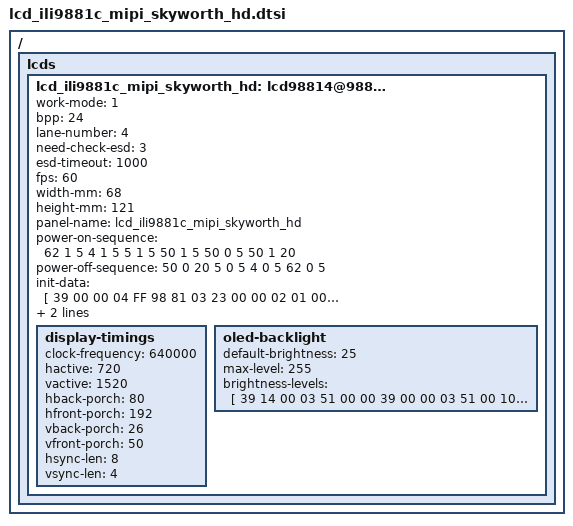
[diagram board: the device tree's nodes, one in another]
/ { lcds {
	lcd_ili9881c_mipi_skyworth_hd: lcd98814@98814 {

		work-mode = <1>;
		bpp = <24>;
		lane-number = <4>;

		need-check-esd = <3>;
		esd-timeout = <1000>;

		fps = <60>;
		width-mm = <68>;
		height-mm = <121>;
		panel-name = "lcd_ili9881c_mipi_skyworth_hd";

		power-on-sequence = <
					62  1  5
					4   1  5
					5   1  5
					50  1  5
					50  0  5
					50  1  20
					>;
		power-off-sequence = <
					50  0  20
					5   0	5
					4   0   5
					62  0  5
					>;

		init-data = [
			39 00 00 04 FF 98 81 03
			23 00 00 02 01 00
			23 00 00 02 02 00
			23 00 00 02 03 53
			23 00 00 02 04 53
			23 00 00 02 05 13
			23 00 00 02 06 04
			23 00 00 02 07 02
			23 00 00 02 08 02
			23 00 00 02 09 00
			23 00 00 02 0a 00
			23 00 00 02 0b 00
			23 00 00 02 0c 00
			23 00 00 02 0d 00
			23 00 00 02 0e 00
			23 00 00 02 0f 00
			23 00 00 02 10 00
			23 00 00 02 11 00
			23 00 00 02 12 00
			23 00 00 02 13 00
			23 00 00 02 14 00
			23 00 00 02 15 00
			23 00 00 02 16 00
			23 00 00 02 17 00
			23 00 00 02 18 00
			23 00 00 02 19 00
			23 00 00 02 1a 00
			23 00 00 02 1b 00
			23 00 00 02 1c 00
			23 00 00 02 1d 00
			23 00 00 02 1e C0
			23 00 00 02 1f 80
			23 00 00 02 20 02
			23 00 00 02 21 09
			23 00 00 02 22 00
			23 00 00 02 23 00
			23 00 00 02 24 00
			23 00 00 02 25 00
			23 00 00 02 26 00
			23 00 00 02 27 00
			23 00 00 02 28 55
			23 00 00 02 29 03
			23 00 00 02 2a 00
			23 00 00 02 2b 00
			23 00 00 02 2c 00
			23 00 00 02 2d 00
			23 00 00 02 2e 00
			23 00 00 02 2f 00
			23 00 00 02 30 00
			23 00 00 02 31 00
			23 00 00 02 32 00
			23 00 00 02 33 00
			23 00 00 02 34 03
			23 00 00 02 35 00
			23 00 00 02 36 05
			23 00 00 02 37 00
			23 00 00 02 38 3C
			23 00 00 02 39 00
			23 00 00 02 3a 00
			23 00 00 02 3b 00
			23 00 00 02 3c 00
			23 00 00 02 3d 00
			23 00 00 02 3e 00
			23 00 00 02 3f 00
			23 00 00 02 40 00
			23 00 00 02 41 00
			23 00 00 02 42 00
			23 00 00 02 43 00
			23 00 00 02 44 00
			23 00 00 02 50 01
			23 00 00 02 51 23
			23 00 00 02 52 45
			23 00 00 02 53 67
			23 00 00 02 54 89
			23 00 00 02 55 ab
			23 00 00 02 56 01
			23 00 00 02 57 23
			23 00 00 02 58 45
			23 00 00 02 59 67
			23 00 00 02 5a 89
			23 00 00 02 5b ab
			23 00 00 02 5c cd
			23 00 00 02 5d ef
			23 00 00 02 5e 01
			23 00 00 02 5f 02
			23 00 00 02 60 02
			23 00 00 02 61 0A
			23 00 00 02 62 08
			23 00 00 02 63 14
			23 00 00 02 64 15
			23 00 00 02 65 0C
			23 00 00 02 66 0D
			23 00 00 02 67 0E
			23 00 00 02 68 0F
			23 00 00 02 69 10
			23 00 00 02 6a 11
			23 00 00 02 6b 06
			23 00 00 02 6c 02
			23 00 00 02 6d 02
			23 00 00 02 6e 02
			23 00 00 02 6f 02
			23 00 00 02 70 02
			23 00 00 02 71 02
			23 00 00 02 72 00
			23 00 00 02 73 02
			23 00 00 02 74 02
			23 00 00 02 75 02
			23 00 00 02 76 02
			23 00 00 02 77 0A
			23 00 00 02 78 06
			23 00 00 02 79 14
			23 00 00 02 7a 15
			23 00 00 02 7b 0F
			23 00 00 02 7c 0E
			23 00 00 02 7d 0D
			23 00 00 02 7e 0C
			23 00 00 02 7f 11
			23 00 00 02 80 10
			23 00 00 02 81 08
			23 00 00 02 82 02
			23 00 00 02 83 02
			23 00 00 02 84 02
			23 00 00 02 85 02
			23 00 00 02 86 02
			23 00 00 02 87 02
			23 00 00 02 88 02
			23 00 00 02 89 02
			23 00 00 02 8A 02
			39 00 00 04 FF 98 81 04
			23 00 00 02 00 82
			23 00 00 02 6C 15
			23 00 00 02 6E 2F
			23 00 00 02 6F 35
			23 00 00 02 3A 92
			23 00 00 02 8D 1F
			23 00 00 02 87 BA
			23 00 00 02 26 76
			23 00 00 02 B2 D1
			23 00 00 02 88 0B
			23 00 00 02 33 14
			23 00 00 02 35 1F
			23 00 00 02 38 01
			23 00 00 02 39 00
			23 00 00 02 7A 0F
			23 00 00 02 B5 06
			23 00 00 02 31 75
			23 00 00 02 3B 98
			39 00 00 04 FF 98 81 01
			23 00 00 02 22 0A
			23 00 00 02 31 00
			23 00 00 02 53 63
			23 00 00 02 55 6E
			23 00 00 02 50 E1
			23 00 00 02 51 DD
			23 00 00 02 60 28
			23 00 00 02 61 00
			23 00 00 02 62 10
			23 00 00 02 63 00
			23 00 00 02 70 51
			23 00 00 02 71 01
			23 00 00 02 2E 04
			23 00 00 02 2F 80
			23 00 00 02 A0 00
			23 00 00 02 A1 14
			23 00 00 02 A2 24
			23 00 00 02 A3 16
			23 00 00 02 A4 1B
			23 00 00 02 A5 2E
			23 00 00 02 A6 22
			23 00 00 02 A7 23
			23 00 00 02 A8 7E
			23 00 00 02 A9 1B
			23 00 00 02 AA 27
			23 00 00 02 AB 65
			23 00 00 02 AC 1A
			23 00 00 02 AD 19
			23 00 00 02 AE 4E
			23 00 00 02 AF 22
			23 00 00 02 B0 29
			23 00 00 02 B1 4A
			23 00 00 02 B2 5B
			23 00 00 02 B3 33
			23 00 00 02 C0 00
			23 00 00 02 C1 14
			23 00 00 02 C2 23
			23 00 00 02 C3 16
			23 00 00 02 C4 1A
			23 00 00 02 C5 2E
			23 00 00 02 C6 22
			23 00 00 02 C7 23
			23 00 00 02 C8 7E
			23 00 00 02 C9 1B
			23 00 00 02 CA 27
			23 00 00 02 CB 64
			23 00 00 02 CC 1A
			23 00 00 02 CD 19
			23 00 00 02 CE 4E
			23 00 00 02 CF 22
			23 00 00 02 D0 29
			23 00 00 02 D1 4A
			23 00 00 02 D2 5B
			23 00 00 02 D3 33
			39 00 00 04 FF 98 81 02
			23 00 00 02 06 20
			23 00 00 02 07 00
			39 00 00 04 FF 98 81 00
			39 00 00 03 68 04 00
			39 00 00 03 51 00 00
			23 00 00 02 53 24
			23 00 00 02 55 01
			39 00 00 03 5E 00 10
			23 00 00 02 35 00
			13 78 00 01 11
			13 14 00 01 29
			];
		sleep-in = [
			13 0A 00 01 28
			13 78 00 01 10
			];
		sleep-out = [
			13 78 00 01 11
			13 64 00 01 29
			];

		display-timings {
			clock-frequency = <640000>;
			hactive = <720>;
			vactive = <1520>;
			hback-porch = <80>;
			hfront-porch = <192>;
			vback-porch = <26>;
			vfront-porch = <50>;
			hsync-len = <8>;
			vsync-len = <4>;
		};
		oled-backlight {
			default-brightness = <25>;
			max-level = <255>;
			brightness-levels = [
				39 14 00 03 51 00 00
				39 00 00 03 51 00 10
				39 00 00 03 51 00 20
				39 00 00 03 51 00 30
				39 00 00 03 51 00 40
				39 00 00 03 51 00 50
				39 00 00 03 51 00 60
				39 00 00 03 51 00 70
				39 00 00 03 51 00 80
				39 00 00 03 51 00 90
				39 00 00 03 51 00 A0
				39 00 00 03 51 00 B0
				39 00 00 03 51 00 C0
				39 00 00 03 51 00 D0
				39 00 00 03 51 00 E0
				39 00 00 03 51 00 F0
				39 00 00 03 51 01 00
				39 00 00 03 51 01 10
				39 00 00 03 51 01 20
				39 00 00 03 51 01 30
				39 00 00 03 51 01 40
				39 00 00 03 51 01 50
				39 00 00 03 51 01 60
				39 00 00 03 51 01 70
				39 00 00 03 51 01 80
				39 00 00 03 51 01 90
				39 00 00 03 51 01 A0
				39 00 00 03 51 01 B0
				39 00 00 03 51 01 C0
				39 00 00 03 51 01 D0
				39 00 00 03 51 01 E0
				39 00 00 03 51 01 F0
				39 00 00 03 51 02 00
				39 00 00 03 51 02 10
				39 00 00 03 51 02 20
				39 00 00 03 51 02 30
				39 00 00 03 51 02 40
				39 00 00 03 51 02 50
				39 00 00 03 51 02 60
				39 00 00 03 51 02 70
				39 00 00 03 51 02 80
				39 00 00 03 51 02 90
				39 00 00 03 51 02 A0
				39 00 00 03 51 02 B0
				39 00 00 03 51 02 C0
				39 00 00 03 51 02 D0
				39 00 00 03 51 02 E0
				39 00 00 03 51 02 F0
				39 00 00 03 51 03 00
				39 00 00 03 51 03 10
				39 00 00 03 51 03 20
				39 00 00 03 51 03 30
				39 00 00 03 51 03 40
				39 00 00 03 51 03 50
				39 00 00 03 51 03 60
				39 00 00 03 51 03 70
				39 00 00 03 51 03 80
				39 00 00 03 51 03 90
				39 00 00 03 51 03 A0
				39 00 00 03 51 03 B0
				39 00 00 03 51 03 C0
				39 00 00 03 51 03 D0
				39 00 00 03 51 03 E0
				39 00 00 03 51 03 F0
				39 00 00 03 51 04 00
				39 00 00 03 51 04 10
				39 00 00 03 51 04 20
				39 00 00 03 51 04 30
				39 00 00 03 51 04 40
				39 00 00 03 51 04 50
				39 00 00 03 51 04 60
				39 00 00 03 51 04 70
				39 00 00 03 51 04 80
				39 00 00 03 51 04 90
				39 00 00 03 51 04 A0
				39 00 00 03 51 04 B0
				39 00 00 03 51 04 C0
				39 00 00 03 51 04 D0
				39 00 00 03 51 04 E0
				39 00 00 03 51 04 F0
				39 00 00 03 51 05 00
				39 00 00 03 51 05 10
				39 00 00 03 51 05 20
				39 00 00 03 51 05 30
				39 00 00 03 51 05 40
				39 00 00 03 51 05 50
				39 00 00 03 51 05 60
				39 00 00 03 51 05 70
				39 00 00 03 51 05 80
				39 00 00 03 51 05 90
				39 00 00 03 51 05 A0
				39 00 00 03 51 05 B0
				39 00 00 03 51 05 C0
				39 00 00 03 51 05 D0
				39 00 00 03 51 05 E0
				39 00 00 03 51 05 F0
				39 00 00 03 51 06 00
				39 00 00 03 51 06 10
				39 00 00 03 51 06 20
				39 00 00 03 51 06 30
				39 00 00 03 51 06 40
				39 00 00 03 51 06 50
				39 00 00 03 51 06 60
				39 00 00 03 51 06 70
				39 00 00 03 51 06 80
				39 00 00 03 51 06 90
				39 00 00 03 51 06 A0
				39 00 00 03 51 06 B0
				39 00 00 03 51 06 C0
				39 00 00 03 51 06 D0
				39 00 00 03 51 06 E0
				39 00 00 03 51 06 F0
				39 00 00 03 51 07 00
				39 00 00 03 51 07 10
				39 00 00 03 51 07 20
				39 00 00 03 51 07 30
				39 00 00 03 51 07 40
				39 00 00 03 51 07 50
				39 00 00 03 51 07 60
				39 00 00 03 51 07 70
				39 00 00 03 51 07 80
				39 00 00 03 51 07 90
				39 00 00 03 51 07 A0
				39 00 00 03 51 07 B0
				39 00 00 03 51 07 C0
				39 00 00 03 51 07 D0
				39 00 00 03 51 07 E0
				39 00 00 03 51 07 F0
				39 00 00 03 51 08 00
				39 00 00 03 51 08 10
				39 00 00 03 51 08 20
				39 00 00 03 51 08 30
				39 00 00 03 51 08 40
				39 00 00 03 51 08 50
				39 00 00 03 51 08 60
				39 00 00 03 51 08 70
				39 00 00 03 51 08 80
				39 00 00 03 51 08 90
				39 00 00 03 51 08 A0
				39 00 00 03 51 08 B0
				39 00 00 03 51 08 C0
				39 00 00 03 51 08 D0
				39 00 00 03 51 08 E0
				39 00 00 03 51 08 F0
				39 00 00 03 51 09 00
				39 00 00 03 51 09 10
				39 00 00 03 51 09 20
				39 00 00 03 51 09 30
				39 00 00 03 51 09 40
				39 00 00 03 51 09 50
				39 00 00 03 51 09 60
				39 00 00 03 51 09 70
				39 00 00 03 51 09 80
				39 00 00 03 51 09 90
				39 00 00 03 51 09 A0
				39 00 00 03 51 09 B0
				39 00 00 03 51 09 C0
				39 00 00 03 51 09 D0
				39 00 00 03 51 09 E0
				39 00 00 03 51 09 F0
				39 00 00 03 51 0A 00
				39 00 00 03 51 0A 10
				39 00 00 03 51 0A 20
				39 00 00 03 51 0A 30
				39 00 00 03 51 0A 40
				39 00 00 03 51 0A 50
				39 00 00 03 51 0A 60
				39 00 00 03 51 0A 70
				39 00 00 03 51 0A 80
				39 00 00 03 51 0A 90
				39 00 00 03 51 0A A0
				39 00 00 03 51 0A B0
				39 00 00 03 51 0A C0
				39 00 00 03 51 0A D0
				39 00 00 03 51 0A E0
				39 00 00 03 51 0A F0
				39 00 00 03 51 0B 00
				39 00 00 03 51 0B 10
				39 00 00 03 51 0B 20
				39 00 00 03 51 0B 30
				39 00 00 03 51 0B 40
				39 00 00 03 51 0B 50
				39 00 00 03 51 0B 60
				39 00 00 03 51 0B 70
				39 00 00 03 51 0B 80
				39 00 00 03 51 0B 90
				39 00 00 03 51 0B A0
				39 00 00 03 51 0B B0
				39 00 00 03 51 0B C0
				39 00 00 03 51 0B D0
				39 00 00 03 51 0B E0
				39 00 00 03 51 0B F0
				39 00 00 03 51 0C 00
				39 00 00 03 51 0C 10
				39 00 00 03 51 0C 20
				39 00 00 03 51 0C 30
				39 00 00 03 51 0C 40
				39 00 00 03 51 0C 50
				39 00 00 03 51 0C 60
				39 00 00 03 51 0C 70
				39 00 00 03 51 0C 80
				39 00 00 03 51 0C 90
				39 00 00 03 51 0C A0
				39 00 00 03 51 0C B0
				39 00 00 03 51 0C C0
				39 00 00 03 51 0C D0
				39 00 00 03 51 0C E0
				39 00 00 03 51 0C F0
				39 00 00 03 51 0D 00
				39 00 00 03 51 0D 10
				39 00 00 03 51 0D 20
				39 00 00 03 51 0D 30
				39 00 00 03 51 0D 40
				39 00 00 03 51 0D 50
				39 00 00 03 51 0D 60
				39 00 00 03 51 0D 70
				39 00 00 03 51 0D 80
				39 00 00 03 51 0D 90
				39 00 00 03 51 0D A0
				39 00 00 03 51 0D B0
				39 00 00 03 51 0D C0
				39 00 00 03 51 0D D0
				39 00 00 03 51 0D E0
				39 00 00 03 51 0D F0
				39 00 00 03 51 0E 00
				39 00 00 03 51 0E 10
				39 00 00 03 51 0E 20
				39 00 00 03 51 0E 30
				39 00 00 03 51 0E 40
				39 00 00 03 51 0E 50
				39 00 00 03 51 0E 60
				39 00 00 03 51 0E 70
				39 00 00 03 51 0E 80
				39 00 00 03 51 0E 90
				39 00 00 03 51 0E A0
				39 00 00 03 51 0E B0
				39 00 00 03 51 0E C0
				39 00 00 03 51 0E D0
				39 00 00 03 51 0E E0
				39 00 00 03 51 0E F0
				39 00 00 03 51 0F 00
				39 00 00 03 51 0F 10
				39 00 00 03 51 0F 20
				39 00 00 03 51 0F 30
				39 00 00 03 51 0F 40
				39 00 00 03 51 0F 50
				39 00 00 03 51 0F 60
				39 00 00 03 51 0F 70
				39 00 00 03 51 0F 80
				39 00 00 03 51 0F 90
				39 00 00 03 51 0F A0
				39 00 00 03 51 0F B0
				39 00 00 03 51 0F C0
				39 00 00 03 51 0F D0
				39 00 00 03 51 0F E0
				39 00 00 03 51 0F F0
			];
		};
	};
};};

